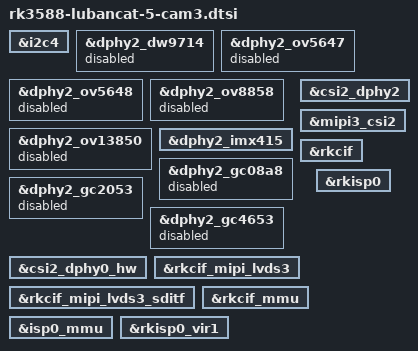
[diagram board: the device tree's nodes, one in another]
&i2c4 {
	status = "okay";
};

&dphy2_dw9714 {
	status = "disabled";
};

&dphy2_ov5647 {
	status = "disabled";
};

&dphy2_ov5648 {
	status = "disabled";
};

&dphy2_ov8858 {
	status = "disabled";
};

&dphy2_ov13850 {
	status = "disabled";
};

&dphy2_imx415 {
	status = "okay";
};

&dphy2_gc08a8 {
	status = "disabled";
};

&dphy2_gc2053 {
	status = "disabled";
};

&dphy2_gc4653 {
	status = "disabled";
};

&csi2_dphy0_hw {
	status = "okay";
};

&csi2_dphy2 {
	status = "okay";
};

&mipi3_csi2 {
	status = "okay";
};

&rkcif {
	status = "okay";
};

&rkcif_mipi_lvds3 {
	status = "okay";
};

&rkcif_mipi_lvds3_sditf {
	status = "okay";
};

&rkcif_mmu {
	status = "okay";
};

&rkisp0 {
	status = "okay";
};

&isp0_mmu {
	status = "okay";
};

&rkisp0_vir1 {
	status = "okay";
};
